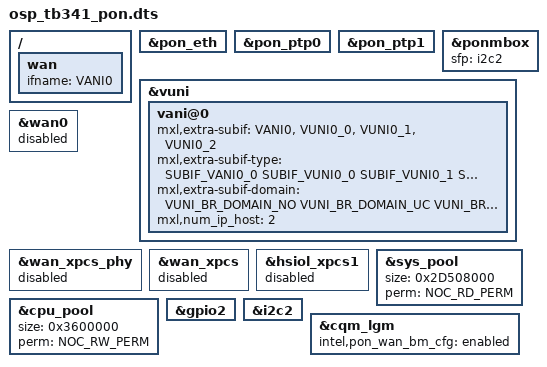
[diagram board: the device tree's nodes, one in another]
// SPDX-License-Identifier: GPL-2.0
/*
 * Copyright (C) 2021-2022 MaxLinear, Inc.
 *
 * This program is free software; you can redistribute it and/or modify it
 * under the terms of the GNU General Public License, as published by the Free
 * Software Foundation; either version 2 of the License, or (at your option)
 * any later version.
 *
 * This program is distributed in the hope that it will be useful, but WITHOUT
 * ANY WARRANTY; without even the implied warranty of MERCHANTABILITY or
 * FITNESS FOR A PARTICULAR PURPOSE.
 * See the GNU General Public License for more details.
 *
 * You should have received a copy of the GNU General Public License along
 * with this program; if not, see <http://www.gnu.org/licenses/>.
 */

/dts-v1/;
#include "osp_tb341.dts"

/ {
	wan {
		ifname = "VANI0";
	};
};

&pon_eth {
	status = "okay";
};

&pon_ptp0 {
	status = "okay";
};

&pon_ptp1 {
	status = "okay";
};

&ponmbox {
	status = "okay";
	/* I2C bus to the optical WAN transceiver */
	sfp = <&i2c2>;
};

&vuni {
	status = "okay";
	vani@0 {
		mxl,extra-subif = "VANI0", "VUNI0_0", "VUNI0_1", "VUNI0_2";
		mxl,extra-subif-type = <SUBIF_VANI0_0 SUBIF_VUNI0_0 SUBIF_VUNI0_1 SUBIF_VUNI0_2>;
		mxl,extra-subif-domain = <VUNI_BR_DOMAIN_NO VUNI_BR_DOMAIN_UC VUNI_BR_DOMAIN_MC VUNI_BR_DOMAIN_BC>;
		mxl,num_ip_host = <2>;
	};
};

&wan0 {
	status = "disabled";
};

/* WAN XPCS PHY */
&wan_xpcs_phy {
	status = "disabled";
};

/* XPCS setting */
&wan_xpcs {
	status = "disabled";
};

&hsiol_xpcs1 {
	status = "disabled";
};

&sys_pool {
	size = <0x2D508000>;
	perm = <NOC_RD_PERM>;
};

&cpu_pool {
	size = <0x3600000>;
	perm = <NOC_RW_PERM>;
};

&gpio2 {
	/delete-node/ sfp_eth_tx_disable;
};

&i2c2 {
	status = "okay";
};

&cqm_lgm {
	intel,pon_wan_bm_cfg = "enabled";	
};
